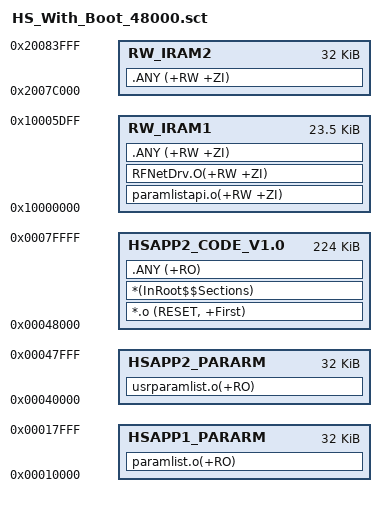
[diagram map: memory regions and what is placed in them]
; *************************************************************
; *** Scatter-Loading Description File generated by uVision ***
; *************************************************************

LR_IROM1 0x00048000 0x00038000  {    ; load region size_region
  HSAPP2_CODE_V1.0 0x00048000 0x00038000  {  ; load address = execution address
   *.o (RESET, +First)
   *(InRoot$$Sections)
   .ANY (+RO)
  }
; total 32+24K RAM
;	26K RAM
  RW_IRAM1 0x10000000 0x00005E00  {  ; RW data  _gRtCarInfoList占用0x10005E00~0x10008000空间，程序__main禁止初始化该空间
   paramlistapi.o(+RW +ZI)              ;   IAP所使用ram区
   RFNetDrv.O(+RW +ZI)                  ;   IAP所使用ram区
   .ANY (+RW +ZI)
  }
;	32K RAM
  RW_IRAM2 0x2007C000 0x00008000  {  ; RW data
   .ANY (+RW +ZI)
  }
}
; 参数区
LR_IROM2 0x00010000 0x00008000  {    ; load region size_region
  HSAPP1_PARARM 0x0010000 0x00008000  {  ; load address = execution address
	paramlist.o(+RO)
  }
}
; 参数区
LR_IROM3 0x00040000 0x00008000  {    ; load region size_region
  HSAPP2_PARARM 0x0040000 0x00008000  {  ; load address = execution address
	usrparamlist.o(+RO)
  }
}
